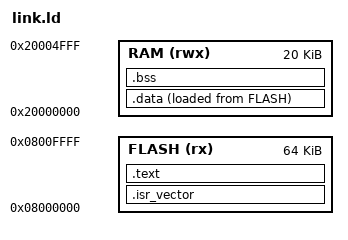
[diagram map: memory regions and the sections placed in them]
MEMORY
{
    FLASH (rx)  : ORIGIN = 0x08000000, LENGTH = 64K
    RAM   (rwx) : ORIGIN = 0x20000000, LENGTH = 20K
}

_stack = ORIGIN(RAM) + LENGTH(RAM);

SECTIONS
{
    .isr_vector :
    {
        KEEP(*(.isr_vector))
    } > FLASH

    .text :
    {
        *(.text*)
        *(.rodata*)
        . = ALIGN(4);
        __preinit_array_start = .;
        KEEP(*(.preinit_array))
        __preinit_array_end = .;
        __init_array_start = .;
        KEEP(*(SORT(.init_array.*)))
        KEEP(*(.init_array))
        __init_array_end = .;
        __fini_array_start = .;
        KEEP(*(SORT(.fini_array.*)))
        KEEP(*(.fini_array))
        __fini_array_end = .;
    } > FLASH

    _sidata = LOADADDR(.data);

    .data :
    {
        _sdata = .;
        *(.data*)
        _edata = .;
    } > RAM AT > FLASH

    .bss :
    {
        . = ALIGN(4);
        _sbss = .;

        *(.bss)
        *(.bss*)
        *(COMMON)

        . = ALIGN(4);
        _ebss = .;
    } >RAM

        PROVIDE(end = .);

}
